VERSION ""

NS_ :

	BU_SG_REL_handbrake_switch
	BU_EV_REL_
	BU_BO_REL_Bool
	SG_MUL_VAL_

BS_:

BU_: REN ROS SEN BEN LVD SHUTDOWN NUC

BO_ 0 AUTO_MODE: 1 REN
 SG_ AUTO_MODE : 0|1@1+ (1,0) [0|1] "Off/On"  Vector__XXX

BO_ 1 MANUAL_MODE: 1 REN
 SG_ MANUAL_MODE : 0|1@1+ (1,0) [0|1] "Off/On"  Vector__XXX

BO_ 2 RC_MODE: 1 REN
 SG_ RC_MODE : 0|1@1+ (1,0) [0|1] "Off/On"  Vector__XXX

BO_ 3 RC_ARMED: 1 REN
 SG_ RC_ARMED : 0|1@1+ (1,0) [0|1] "Off/On"  Vector__XXX

BO_ 4 COLLISION_DETECTED: 1 NUC
 SG_ COLLISION_DETECTED : 0|1@1+ (1,0) [0|1] "Off/On"  Vector__XXX

BO_ 5 RC_STEER_ANG_CMD: 1 REN
 SG_ RC_STEER_ANG_CMD : 0|8@1+ (0.7,-90) [-45|45] "deg" Vector__XXX

BO_ 6 RC_BRK_CMD: 1 REN
 SG_ RC_BRK_CMD : 0|8@1+ (8,0) [0|2000] "PSI" Vector__XXX

BO_ 7 RC_THROTTLE_CMD: 1 REN
 SG_ RC_THROTTLE_CMD : 0|8@1+ (0.4,0) [0|100] "%"  Vector__XXX

BO_ 8 ROS_RPM_CMD: 2 ROS
 SG_ ROS_RPM_CMD : 0|16@1+ (1,0) [0|20000] "rpm" Vector__XXX

BO_ 9 ROS_STEER_ANG_CMD: 1 ROS
 SG_ ROS_STEER_ANG_CMD : 0|8@1+ (0.7,-90) [-45|45] "deg" Vector__XXX

BO_ 10 ROS_RMOTOR_RPM_CMD: 2 ROS
 SG_ ROS_RMOTOR_RPM_CMD : 0|16@1+ (1,0) [0|20000] "rpm" Vector__XXX

BO_ 11 ROS_LMOTOR_RPM_CMD: 2 ROS
 SG_ ROS_LMOTOR_RPM_CMD : 0|16@1+ (1,0) [0|20000] "rpm" Vector__XXX

BO_ 12 AUTO_BRK_CMD: 1 LVD
 SG_ AUTO_BRK_CMD : 0|8@1+ (8,0) [0|2000] "PSI" Vector__XXX

BO_ 13 STEER_ANG_ACTUAL: 1 SEN
 SG_ STEER_ANG_ACTUAL :  0|8@1+ (0.7,-90) [-45|45]  "deg" Vector__XXX

BO_ 14 BRKPRS_R: 1 BEN
 SG_ BRKPRS_R : 0|8@1+ (8,0) [0|2000] "PSI" Vector__XXX

BO_ 15 BRKPRS_F: 1 BEN
 SG_ BRKPRS_F : 0|8@1+ (8,0) [0|2000] "PSI" Vector__XXX

BO_ 16 BRK_PSI_CMD: 1 LVD
 SG_ BRK_PSI_CMD : 0|8@1+ (8,0) [0|2000] "PSI" Vector__XXX

BO_ 17 STEER_ANG_CMD: 1 LVD
 SG_ STEER_ANG_CMD : 0|8@1+ (0.7,-90) [-45|45] "deg" Vector__XXX

BO_ 20 ESTOP_REMOTE: 1 SHUTDOWN
 SG_ ESTOP_REMOTE : 0|1@1+ (1,0) [0|1] "Off/On"  Vector__XXX

BO_ 21 ESTOP_CAR: 1 SHUTDOWN
 SG_ ESTOP_CAR : 0|1@1+ (1,0) [0|1] "Off/On"  Vector__XXX

BO_ 22 HB_BEN: 1 BEN
 SG_ HB_BEN : 0|1@1+ (1,0) [0|1] "Good/Bad"  Vector__XXX

BO_ 23 HB_SEN: 1 SEN
 SG_ HB_SEN : 0|1@1+ (1,0) [0|1] "Good/Bad"  Vector__XXX

BO_ 24 HB_REN: 1 REN
 SG_ HB_REN : 0|1@1+ (1,0) [0|1] "Good/Bad"  Vector__XXX

BO_ 25 HB_LVD: 1 LVD
 SG_ HB_LVD : 0|1@1+ (1,0) [0|1] "Good/Bad"  Vector__XXX

BO_ 26 HB_PRE: 1 PRECHARGE
 SG_ HB_PRE : 0|1@1+ (1,0) [0|1] "Good/Bad"  Vector__XXX

BO_ 27 RC_ERROR: 1 AVONE
 SG_ RC_ERROR : 0|1@1+ (1,0) [0|1] "Good/Bad"  Vector__XXX

BO_ 28 BRAKE_ERROR: 1 AVONE
 SG_ BRAKE_ERROR : 0|1@1+ (1,0) [0|1] "Good/Bad"  Vector__XXX

BO_ 29 STEER_ERROR: 1 AVONE
 SG_ STEER_ERROR : 0|1@1+ (1,0) [0|1] "Good/Bad"  Vector__XXX

BO_ 30 AVG_WHEELSPEED: 2 LVD
 SG_ AVG_WHEELSPEED : 0|16@1+ (1,0) [0|20000] "rpm" Vector__XXX

BO_ 50 NAV2_CANCEL_CMD: 1 REN
 SG_ NAV2_CANCEL_CMD : 0|8@1+ (1,0) [0|1] ""  Vector__XXX

BO_ 51 NAV2_START_CMD: 1 REN
 SG_ NAV2_START_CMD : 0|8@1+ (1,0) [0|1] ""  Vector__XXX

BO_ 69 AVONE_STATE: 1 AVONE
 SG_ DRIVE_STATE : 0|8@1+ (1,0) [0|6] "state"  Vector__XXX

VAL_ DRIVE_STATE 0 "IDLE" 1 "MANUAL" 2 "RC" 3 "AUTO" 4 "EMERGENCY_BRAKE" 5 "CHARGING";

BO_ 70  FAULT_LATCHED : 2 LVD
 SG_ FAULT_LATCHED : 0|16@1+ (1,0) [0|1] "" Vector__XXX

BO_ 71  BEN_TIMEOUT : 2 LVD
 SG_ BEN_TIMEOUT : 0|16@1+ (1,0) [0|1] "" Vector__XXX

BO_ 72  SEN_TIMEOUT : 2 LVD
 SG_ SEN_TIMEOUT : 0|16@1+ (1,0) [0|1] "" Vector__XXX

BO_ 73  REN_TIMEOUT : 2 LVD
 SG_ REN_TIMEOUT : 0|16@1+ (1,0) [0|1] "" Vector__XXX

BO_ 74  PRE_TIMEOUT : 2 LVD
 SG_ PRE_TIMEOUT : 0|16@1+ (1,0) [0|1] "" Vector__XXX

BO_ 75  ERR_MOTOR : 2 LVD
 SG_ ERR_MOTOR : 0|16@1+ (1,0) [0|1] "" Vector__XXX

BO_ 101 TIMER: 2 LVD
 SG_ GLOBAL_TIME : 0|16@1+ (1,0) [0|65535] "ms/50" Vector__XXX

BO_ 250 CHARGE: 1 CHG
 SG_ CHARGE : 0|1@1+ (1,0) [0|1] "Off/On" Vector__XXX

BO_ 251 CHARGE_ACK: 1 PRE
 SG_ CHARGE_ACK : 0|1@1+ (1,0) [0|1] "Off/On" Vector__XXX

BO_ 256 CMD_HEARTBEAT: 1 ROS
 SG_ CMD_HEARTBEAT : 0|8@1+ (1,0) [0|1] "" Vector__XXX

BO_ 257 ROS_HEARTBEAT: 1 ROS
 SG_ ROS_HEARTBEAT : 0|8@1+ (1,0) [0|1] "" Vector__XXX

BO_ 258 NUC_HEARTBEAT: 1 ROS
 SG_ NUC_HEARTBEAT : 0|8@1+ (1,0) [0|1] "" Vector__XXX

BO_ 272 R2D_STATUS: 1 AVONE
 SG_ R2D_RDY : 0|1@1+ (1,0) [0|1] "Good/Bad"  Vector__XXX

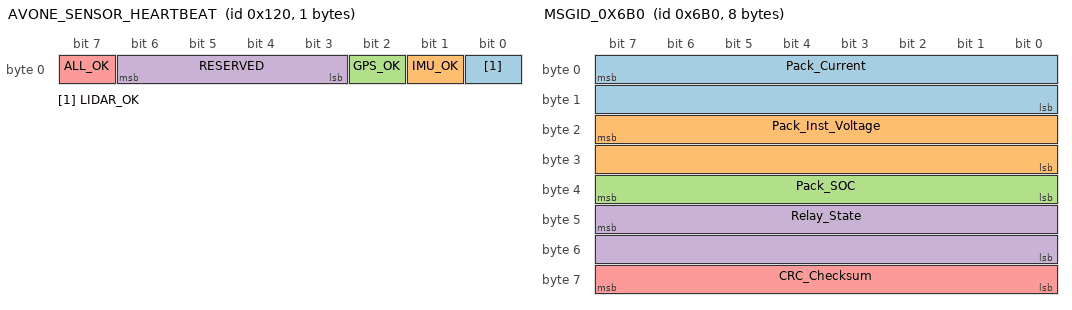
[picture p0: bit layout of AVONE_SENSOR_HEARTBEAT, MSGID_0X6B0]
BO_ 288 AVONE_SENSOR_HEARTBEAT: 1 AVONE
 SG_ LIDAR_OK  : 0|1@1+ (1,0) [0|1] ""  AVONE
 SG_ IMU_OK    : 1|1@1+ (1,0) [0|1] ""  AVONE
 SG_ GPS_OK    : 2|1@1+ (1,0) [0|1] ""  AVONE
 SG_ RESERVED  : 3|4@1+ (1,0) [0|15] "" AVONE
 SG_ ALL_OK    : 7|1@1+ (1,0) [0|1] ""  AVONE

BO_ 532 TS_STATE: 1 PRE
 SG_ TS_STATE : 0|1@1+ (1,0) [0|1] "Good/Bad"  DEN

BO_ 1712 MSGID_0X6B0: 8 BMS
 SG_ Pack_Current : 7|16@0+ (0.1,0) [0|1000] "Amps"  Third_Party_Device
 SG_ Pack_Inst_Voltage : 23|16@0+ (0.1,0) [0|1000] "Volts"  Third_Party_Device
 SG_ Pack_SOC : 39|8@0+ (0.5,0) [0|100] "Percent"  Third_Party_Device
 SG_ Relay_State : 47|16@0+ (1.0,0) [0|10] ""  Third_Party_Device
 SG_ CRC_Checksum : 63|8@0+ (1.0,1720) [0|255] ""  Third_Party_Device

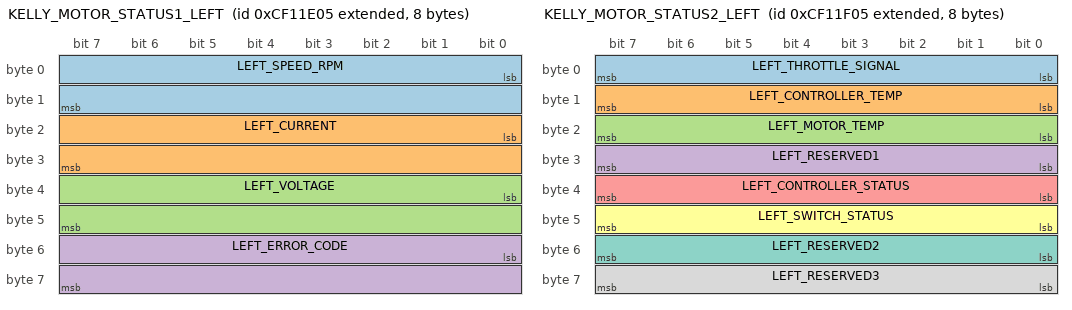
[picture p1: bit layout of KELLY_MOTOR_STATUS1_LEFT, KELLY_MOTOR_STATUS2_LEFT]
BO_ 2364612101 KELLY_MOTOR_STATUS1_LEFT: 8 Controller
 SG_ LEFT_SPEED_RPM         : 0|16@1+ (1,0)     [0|6000]  "rpm"    Vector__XXX
 SG_ LEFT_CURRENT           : 16|16@1+ (0.1,0)  [0|400]   "A"      Vector__XXX
 SG_ LEFT_VOLTAGE           : 32|16@1+ (0.1,0)  [0|180]   "V"      Vector__XXX
 SG_ LEFT_ERROR_CODE        : 48|16@1+ (1,0)    [0|65535] ""       Vector__XXX

BO_ 2364612357 KELLY_MOTOR_STATUS2_LEFT: 8 Controller
 SG_ LEFT_THROTTLE_SIGNAL      : 0|8@1+  (1,0)     [0|255]   "ADC"     Vector__XXX
 SG_ LEFT_CONTROLLER_TEMP      : 8|8@1+  (1,-40)   [-40|215] "C"       Vector__XXX
 SG_ LEFT_MOTOR_TEMP           : 16|8@1+ (1,-30)   [-30|225] "C"       Vector__XXX
 SG_ LEFT_RESERVED1            : 24|8@1+ (1,0)     [0|255]   ""        Vector__XXX
 SG_ LEFT_CONTROLLER_STATUS    : 32|8@1+ (1,0)     [0|255]   "bits"    Vector__XXX
 SG_ LEFT_SWITCH_STATUS        : 40|8@1+ (1,0)     [0|255]   "bits"    Vector__XXX
 SG_ LEFT_RESERVED2            : 48|8@1+ (1,0)     [0|255]   ""        Vector__XXX
 SG_ LEFT_RESERVED3            : 56|8@1+ (1,0)     [0|255]   ""        Vector__XXX

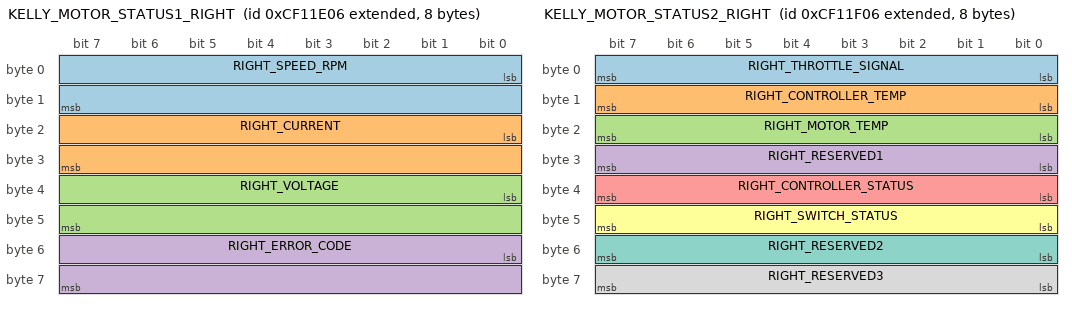
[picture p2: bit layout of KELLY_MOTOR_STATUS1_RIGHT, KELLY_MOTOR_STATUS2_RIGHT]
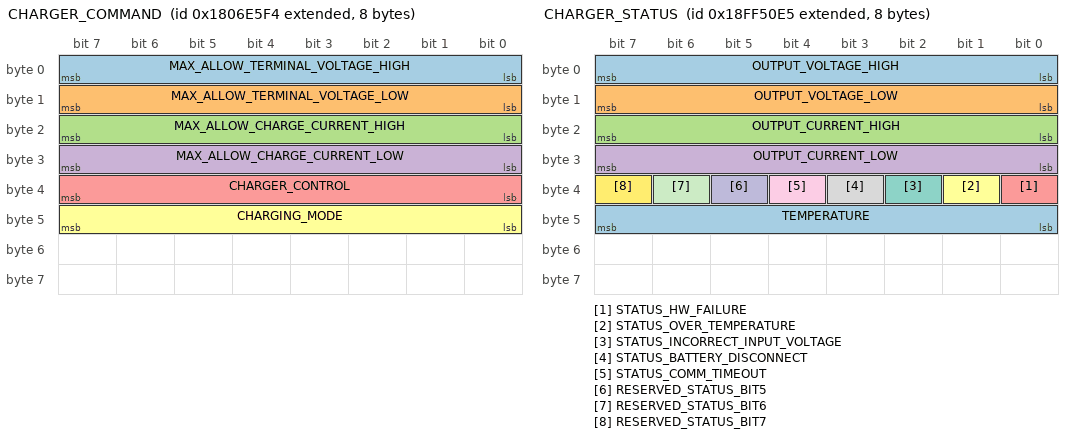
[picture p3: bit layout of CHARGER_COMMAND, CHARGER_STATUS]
BO_ 2364612102 KELLY_MOTOR_STATUS1_RIGHT: 8 Controller
 SG_ RIGHT_SPEED_RPM         : 0|16@1+ (1,0)     [0|6000]  "rpm"    Vector__XXX
 SG_ RIGHT_CURRENT           : 16|16@1+ (0.1,0)  [0|400]   "A"      Vector__XXX
 SG_ RIGHT_VOLTAGE           : 32|16@1+ (0.1,0)  [0|180]   "V"      Vector__XXX
 SG_ RIGHT_ERROR_CODE        : 48|16@1+ (1,0)    [0|65535] ""       Vector__XXX

BO_ 2364612358 KELLY_MOTOR_STATUS2_RIGHT: 8 Controller
 SG_ RIGHT_THROTTLE_SIGNAL      : 0|8@1+  (1,0)     [0|255]   "ADC"     Vector__XXX
 SG_ RIGHT_CONTROLLER_TEMP      : 8|8@1+  (1,-40)   [-40|215] "C"       Vector__XXX
 SG_ RIGHT_MOTOR_TEMP           : 16|8@1+ (1,-30)   [-30|225] "C"       Vector__XXX
 SG_ RIGHT_RESERVED1            : 24|8@1+ (1,0)     [0|255]   ""        Vector__XXX
 SG_ RIGHT_CONTROLLER_STATUS    : 32|8@1+ (1,0)     [0|255]   "bits"    Vector__XXX
 SG_ RIGHT_SWITCH_STATUS        : 40|8@1+ (1,0)     [0|255]   "bits"    Vector__XXX
 SG_ RIGHT_RESERVED2            : 48|8@1+ (1,0)     [0|255]   ""        Vector__XXX
 SG_ RIGHT_RESERVED3            : 56|8@1+ (1,0)     [0|255]   ""        Vector__XXX

BO_ 2550173648 DCDC_COMMAND: 1 CEN
 SG_ DCDC_COMMAND : 0|2@1+ (1,0) [0|2] "On/Off" Vector__XXX

 BO_ 2550255759 DCDC_DATA: 8 DCDC
 SG_ DCDC_TEMP : 63|8@0- (1,-60) [-60|195] "C" Vector__XXX
 SG_ DCDC_WARM_TEMP : 40|1@0+ (1,0) [0|1] "Good/Bad" Vector__XXX
 SG_ DCDC_OVER_TEMP : 41|1@0+ (1,0) [0|1] "Good/Bad" Vector__XXX
 SG_ DCDC_OVER_VOL_INPUT : 42|1@0+ (1,0) [0|1] "Good/Bad" Vector__XXX
 SG_ DCDC_LOW_VOL_INPUT : 43|1@0+ (1,0) [0|1] "Good/Bad" Vector__XXX
 SG_ DCDC_OVER_VOL_OUTPUT : 44|1@0+ (1,0) [0|1] "Good/Bad" Vector__XXX
 SG_ DCDC_LOW_VOL_OUTPUT : 45|1@0+ (1,0) [0|1] "Good/Bad" Vector__XXX
 SG_ DCDC_OVER_CUR_OUTPUT : 46|1@0+ (1,0) [0|1] "Good/Bad" Vector__XXX
 SG_ DCDC_READY : 32|1@0+ (1,0) [0|1] "Good/Bad" Vector__XXX
 SG_ DCDC_STATUS : 33|1@0+ (1,0) [0|1] "Off/On" Vector__XXX
 SG_ DCDC_HARD_FAULT : 34|1@0+ (1,0) [0|1] "Good/Bad" Vector__XXX
 SG_ DCDC_ERR_CAN : 35|1@0+ (1,0) [0|1] "Good/Bad" Vector__XXX
 SG_ DCDC_FAN_CON : 36|1@0+ (1,0) [0|1] "Good/Bad" Vector__XXX
 SG_ DCDC_STOP_ERROR : 37|1@0+ (1,0) [0|1] "Good/Bad" Vector__XXX
 SG_ DCDC_WATER_CON : 38|1@0+ (1,0) [0|1] "Good/Bad" Vector__XXX
 SG_ DCDC_HVIL_ERR : 39|1@0+ (1,0) [0|1] "Good/Bad" Vector__XXX
 SG_ DCDC_CURRENT : 23|16@0+ (0.1,0) [0|100] "A" Vector__XXX
 SG_ DCDC_VOLTAGE : 7|16@0+ (0.1,0) [0|100] "V" Vector__XXX

 BO_ 2550588916 CHARGER_COMMAND: 8 BMS
 SG_ MAX_ALLOW_TERMINAL_VOLTAGE_HIGH : 0|8@1+ (0.1,0) [0|255] "0.1V" Vector__XXX
 SG_ MAX_ALLOW_TERMINAL_VOLTAGE_LOW  : 8|8@1+ (0.1,0) [0|255] "0.1V" Vector__XXX
 SG_ MAX_ALLOW_CHARGE_CURRENT_HIGH   : 16|8@1+ (0.1,0) [0|255] "0.1A" Vector__XXX
 SG_ MAX_ALLOW_CHARGE_CURRENT_LOW    : 24|8@1+ (0.1,0) [0|255] "0.1A" Vector__XXX
 SG_ CHARGER_CONTROL                  : 32|8@1+ (1,0)   [0|1]   "On/Off" Vector__XXX
 SG_ CHARGING_MODE                    : 40|8@1+ (1,0)   [0|1]   "Charge/Heat" Vector__XXX

BO_ 2566869221 CHARGER_STATUS: 8 Charger
 SG_ OUTPUT_VOLTAGE_HIGH             : 0|8@1+ (0.1,0) [0|255] "0.1V" Vector__XXX
 SG_ OUTPUT_VOLTAGE_LOW              : 8|8@1+ (0.1,0) [0|255] "0.1V" Vector__XXX
 SG_ OUTPUT_CURRENT_HIGH             : 16|8@1+ (0.1,0) [0|255] "0.1A" Vector__XXX
 SG_ OUTPUT_CURRENT_LOW              : 24|8@1+ (0.1,0) [0|255] "0.1A" Vector__XXX
 SG_ STATUS_HW_FAILURE               : 32|1@1+ (1,0)   [0|1]   "Good/Bad"   Vector__XXX
 SG_ STATUS_OVER_TEMPERATURE         : 33|1@1+ (1,0)   [0|1]   "Good/Bad"   Vector__XXX
 SG_ STATUS_INCORRECT_INPUT_VOLTAGE  : 34|1@1+ (1,0)   [0|1]   "Good/Bad"   Vector__XXX
 SG_ STATUS_BATTERY_DISCONNECT       : 35|1@1+ (1,0)   [0|1]   "Good/Bad"   Vector__XXX
 SG_ STATUS_COMM_TIMEOUT             : 36|1@1+ (1,0)   [0|1]   "Good/Bad"   Vector__XXX
 SG_ RESERVED_STATUS_BIT5            : 37|1@1+ (1,0)   [0|1]   "Good/Bad"   Vector__XXX
 SG_ RESERVED_STATUS_BIT6            : 38|1@1+ (1,0)   [0|1]   "Good/Bad"   Vector__XXX
 SG_ RESERVED_STATUS_BIT7            : 39|1@1+ (1,0)   [0|1]   "Good/Bad"   Vector__XXX
 SG_ TEMPERATURE                      : 40|8@1+ (1,0) [-40|215] "C"         Vector__XXX
